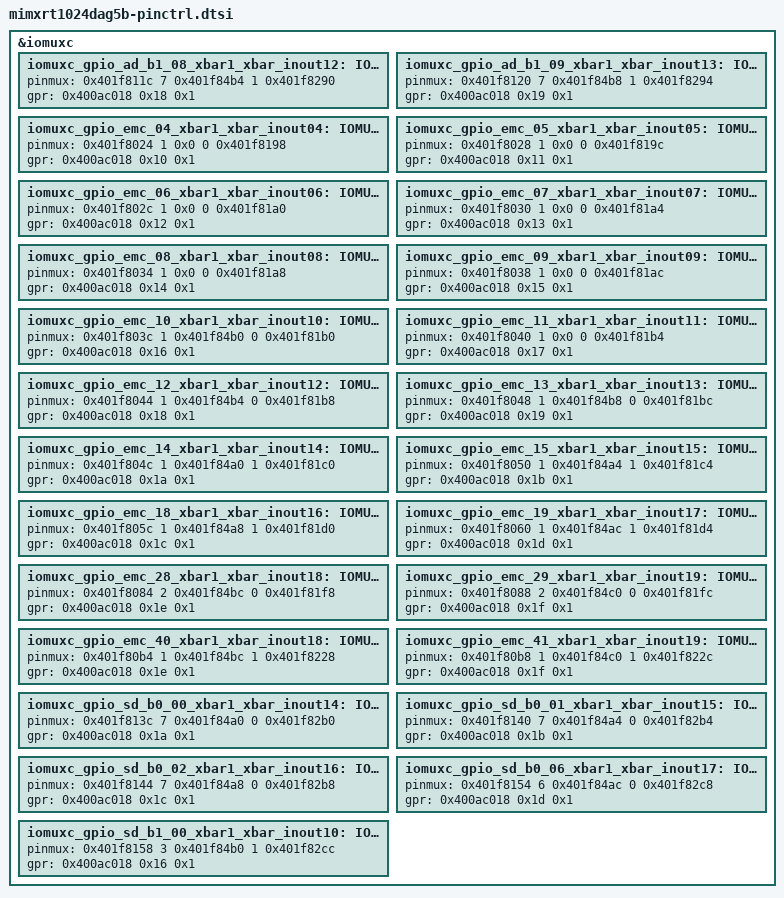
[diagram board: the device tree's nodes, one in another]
/*
 * Copyright 2024, NXP
 * SPDX-License-Identifier: Apache-2.0
 *
 * Note: File generated by gen_soc_headers.py
 * from configuration data for MIMXRT1024DAG5B
 */

/*
 * Delta-deduplicated by dedup_pinctrl.py:
 * based on mimxrt1024dag5a-pinctrl.dtsi with this part's differences applied
 * below (3 removed, 25 changed,
 * 0 added). Regenerate with dedup_pinctrl.py;
 * do not edit by hand.
 * target-hash: 459db1daa55398a1
 */

#include "mimxrt1024dag5a-pinctrl.dtsi"

/delete-node/ &iomuxc_gpio_ad_b0_13_arm_trace1;
/delete-node/ &iomuxc_gpio_ad_b0_14_arm_trace2;
/delete-node/ &iomuxc_gpio_ad_b0_15_arm_trace3;
/delete-node/ &iomuxc_gpio_ad_b1_08_xbar1_xbar_inout12;
/delete-node/ &iomuxc_gpio_ad_b1_09_xbar1_xbar_inout13;
/delete-node/ &iomuxc_gpio_emc_04_xbar1_xbar_inout04;
/delete-node/ &iomuxc_gpio_emc_05_xbar1_xbar_inout05;
/delete-node/ &iomuxc_gpio_emc_06_xbar1_xbar_inout06;
/delete-node/ &iomuxc_gpio_emc_07_xbar1_xbar_inout07;
/delete-node/ &iomuxc_gpio_emc_08_xbar1_xbar_inout08;
/delete-node/ &iomuxc_gpio_emc_09_xbar1_xbar_inout09;
/delete-node/ &iomuxc_gpio_emc_10_xbar1_xbar_inout10;
/delete-node/ &iomuxc_gpio_emc_11_xbar1_xbar_inout11;
/delete-node/ &iomuxc_gpio_emc_12_xbar1_xbar_inout12;
/delete-node/ &iomuxc_gpio_emc_13_xbar1_xbar_inout13;
/delete-node/ &iomuxc_gpio_emc_14_xbar1_xbar_inout14;
/delete-node/ &iomuxc_gpio_emc_15_xbar1_xbar_inout15;
/delete-node/ &iomuxc_gpio_emc_18_xbar1_xbar_inout16;
/delete-node/ &iomuxc_gpio_emc_19_xbar1_xbar_inout17;
/delete-node/ &iomuxc_gpio_emc_28_xbar1_xbar_inout18;
/delete-node/ &iomuxc_gpio_emc_29_xbar1_xbar_inout19;
/delete-node/ &iomuxc_gpio_emc_40_xbar1_xbar_inout18;
/delete-node/ &iomuxc_gpio_emc_41_xbar1_xbar_inout19;
/delete-node/ &iomuxc_gpio_sd_b0_00_xbar1_xbar_inout14;
/delete-node/ &iomuxc_gpio_sd_b0_01_xbar1_xbar_inout15;
/delete-node/ &iomuxc_gpio_sd_b0_02_xbar1_xbar_inout16;
/delete-node/ &iomuxc_gpio_sd_b0_06_xbar1_xbar_inout17;
/delete-node/ &iomuxc_gpio_sd_b1_00_xbar1_xbar_inout10;

&iomuxc {
	/omit-if-no-ref/ iomuxc_gpio_ad_b1_08_xbar1_xbar_inout12: IOMUXC_GPIO_AD_B1_08_XBAR1_XBAR_INOUT12 {
		pinmux = <0x401f811c 7 0x401f84b4 1 0x401f8290>;
		gpr = <0x400ac018 0x18 0x1>;
	};
	/omit-if-no-ref/ iomuxc_gpio_ad_b1_09_xbar1_xbar_inout13: IOMUXC_GPIO_AD_B1_09_XBAR1_XBAR_INOUT13 {
		pinmux = <0x401f8120 7 0x401f84b8 1 0x401f8294>;
		gpr = <0x400ac018 0x19 0x1>;
	};
	/omit-if-no-ref/ iomuxc_gpio_emc_04_xbar1_xbar_inout04: IOMUXC_GPIO_EMC_04_XBAR1_XBAR_INOUT04 {
		pinmux = <0x401f8024 1 0x0 0 0x401f8198>;
		gpr = <0x400ac018 0x10 0x1>;
	};
	/omit-if-no-ref/ iomuxc_gpio_emc_05_xbar1_xbar_inout05: IOMUXC_GPIO_EMC_05_XBAR1_XBAR_INOUT05 {
		pinmux = <0x401f8028 1 0x0 0 0x401f819c>;
		gpr = <0x400ac018 0x11 0x1>;
	};
	/omit-if-no-ref/ iomuxc_gpio_emc_06_xbar1_xbar_inout06: IOMUXC_GPIO_EMC_06_XBAR1_XBAR_INOUT06 {
		pinmux = <0x401f802c 1 0x0 0 0x401f81a0>;
		gpr = <0x400ac018 0x12 0x1>;
	};
	/omit-if-no-ref/ iomuxc_gpio_emc_07_xbar1_xbar_inout07: IOMUXC_GPIO_EMC_07_XBAR1_XBAR_INOUT07 {
		pinmux = <0x401f8030 1 0x0 0 0x401f81a4>;
		gpr = <0x400ac018 0x13 0x1>;
	};
	/omit-if-no-ref/ iomuxc_gpio_emc_08_xbar1_xbar_inout08: IOMUXC_GPIO_EMC_08_XBAR1_XBAR_INOUT08 {
		pinmux = <0x401f8034 1 0x0 0 0x401f81a8>;
		gpr = <0x400ac018 0x14 0x1>;
	};
	/omit-if-no-ref/ iomuxc_gpio_emc_09_xbar1_xbar_inout09: IOMUXC_GPIO_EMC_09_XBAR1_XBAR_INOUT09 {
		pinmux = <0x401f8038 1 0x0 0 0x401f81ac>;
		gpr = <0x400ac018 0x15 0x1>;
	};
	/omit-if-no-ref/ iomuxc_gpio_emc_10_xbar1_xbar_inout10: IOMUXC_GPIO_EMC_10_XBAR1_XBAR_INOUT10 {
		pinmux = <0x401f803c 1 0x401f84b0 0 0x401f81b0>;
		gpr = <0x400ac018 0x16 0x1>;
	};
	/omit-if-no-ref/ iomuxc_gpio_emc_11_xbar1_xbar_inout11: IOMUXC_GPIO_EMC_11_XBAR1_XBAR_INOUT11 {
		pinmux = <0x401f8040 1 0x0 0 0x401f81b4>;
		gpr = <0x400ac018 0x17 0x1>;
	};
	/omit-if-no-ref/ iomuxc_gpio_emc_12_xbar1_xbar_inout12: IOMUXC_GPIO_EMC_12_XBAR1_XBAR_INOUT12 {
		pinmux = <0x401f8044 1 0x401f84b4 0 0x401f81b8>;
		gpr = <0x400ac018 0x18 0x1>;
	};
	/omit-if-no-ref/ iomuxc_gpio_emc_13_xbar1_xbar_inout13: IOMUXC_GPIO_EMC_13_XBAR1_XBAR_INOUT13 {
		pinmux = <0x401f8048 1 0x401f84b8 0 0x401f81bc>;
		gpr = <0x400ac018 0x19 0x1>;
	};
	/omit-if-no-ref/ iomuxc_gpio_emc_14_xbar1_xbar_inout14: IOMUXC_GPIO_EMC_14_XBAR1_XBAR_INOUT14 {
		pinmux = <0x401f804c 1 0x401f84a0 1 0x401f81c0>;
		gpr = <0x400ac018 0x1a 0x1>;
	};
	/omit-if-no-ref/ iomuxc_gpio_emc_15_xbar1_xbar_inout15: IOMUXC_GPIO_EMC_15_XBAR1_XBAR_INOUT15 {
		pinmux = <0x401f8050 1 0x401f84a4 1 0x401f81c4>;
		gpr = <0x400ac018 0x1b 0x1>;
	};
	/omit-if-no-ref/ iomuxc_gpio_emc_18_xbar1_xbar_inout16: IOMUXC_GPIO_EMC_18_XBAR1_XBAR_INOUT16 {
		pinmux = <0x401f805c 1 0x401f84a8 1 0x401f81d0>;
		gpr = <0x400ac018 0x1c 0x1>;
	};
	/omit-if-no-ref/ iomuxc_gpio_emc_19_xbar1_xbar_inout17: IOMUXC_GPIO_EMC_19_XBAR1_XBAR_INOUT17 {
		pinmux = <0x401f8060 1 0x401f84ac 1 0x401f81d4>;
		gpr = <0x400ac018 0x1d 0x1>;
	};
	/omit-if-no-ref/ iomuxc_gpio_emc_28_xbar1_xbar_inout18: IOMUXC_GPIO_EMC_28_XBAR1_XBAR_INOUT18 {
		pinmux = <0x401f8084 2 0x401f84bc 0 0x401f81f8>;
		gpr = <0x400ac018 0x1e 0x1>;
	};
	/omit-if-no-ref/ iomuxc_gpio_emc_29_xbar1_xbar_inout19: IOMUXC_GPIO_EMC_29_XBAR1_XBAR_INOUT19 {
		pinmux = <0x401f8088 2 0x401f84c0 0 0x401f81fc>;
		gpr = <0x400ac018 0x1f 0x1>;
	};
	/omit-if-no-ref/ iomuxc_gpio_emc_40_xbar1_xbar_inout18: IOMUXC_GPIO_EMC_40_XBAR1_XBAR_INOUT18 {
		pinmux = <0x401f80b4 1 0x401f84bc 1 0x401f8228>;
		gpr = <0x400ac018 0x1e 0x1>;
	};
	/omit-if-no-ref/ iomuxc_gpio_emc_41_xbar1_xbar_inout19: IOMUXC_GPIO_EMC_41_XBAR1_XBAR_INOUT19 {
		pinmux = <0x401f80b8 1 0x401f84c0 1 0x401f822c>;
		gpr = <0x400ac018 0x1f 0x1>;
	};
	/omit-if-no-ref/ iomuxc_gpio_sd_b0_00_xbar1_xbar_inout14: IOMUXC_GPIO_SD_B0_00_XBAR1_XBAR_INOUT14 {
		pinmux = <0x401f813c 7 0x401f84a0 0 0x401f82b0>;
		gpr = <0x400ac018 0x1a 0x1>;
	};
	/omit-if-no-ref/ iomuxc_gpio_sd_b0_01_xbar1_xbar_inout15: IOMUXC_GPIO_SD_B0_01_XBAR1_XBAR_INOUT15 {
		pinmux = <0x401f8140 7 0x401f84a4 0 0x401f82b4>;
		gpr = <0x400ac018 0x1b 0x1>;
	};
	/omit-if-no-ref/ iomuxc_gpio_sd_b0_02_xbar1_xbar_inout16: IOMUXC_GPIO_SD_B0_02_XBAR1_XBAR_INOUT16 {
		pinmux = <0x401f8144 7 0x401f84a8 0 0x401f82b8>;
		gpr = <0x400ac018 0x1c 0x1>;
	};
	/omit-if-no-ref/ iomuxc_gpio_sd_b0_06_xbar1_xbar_inout17: IOMUXC_GPIO_SD_B0_06_XBAR1_XBAR_INOUT17 {
		pinmux = <0x401f8154 6 0x401f84ac 0 0x401f82c8>;
		gpr = <0x400ac018 0x1d 0x1>;
	};
	/omit-if-no-ref/ iomuxc_gpio_sd_b1_00_xbar1_xbar_inout10: IOMUXC_GPIO_SD_B1_00_XBAR1_XBAR_INOUT10 {
		pinmux = <0x401f8158 3 0x401f84b0 1 0x401f82cc>;
		gpr = <0x400ac018 0x16 0x1>;
	};
};
